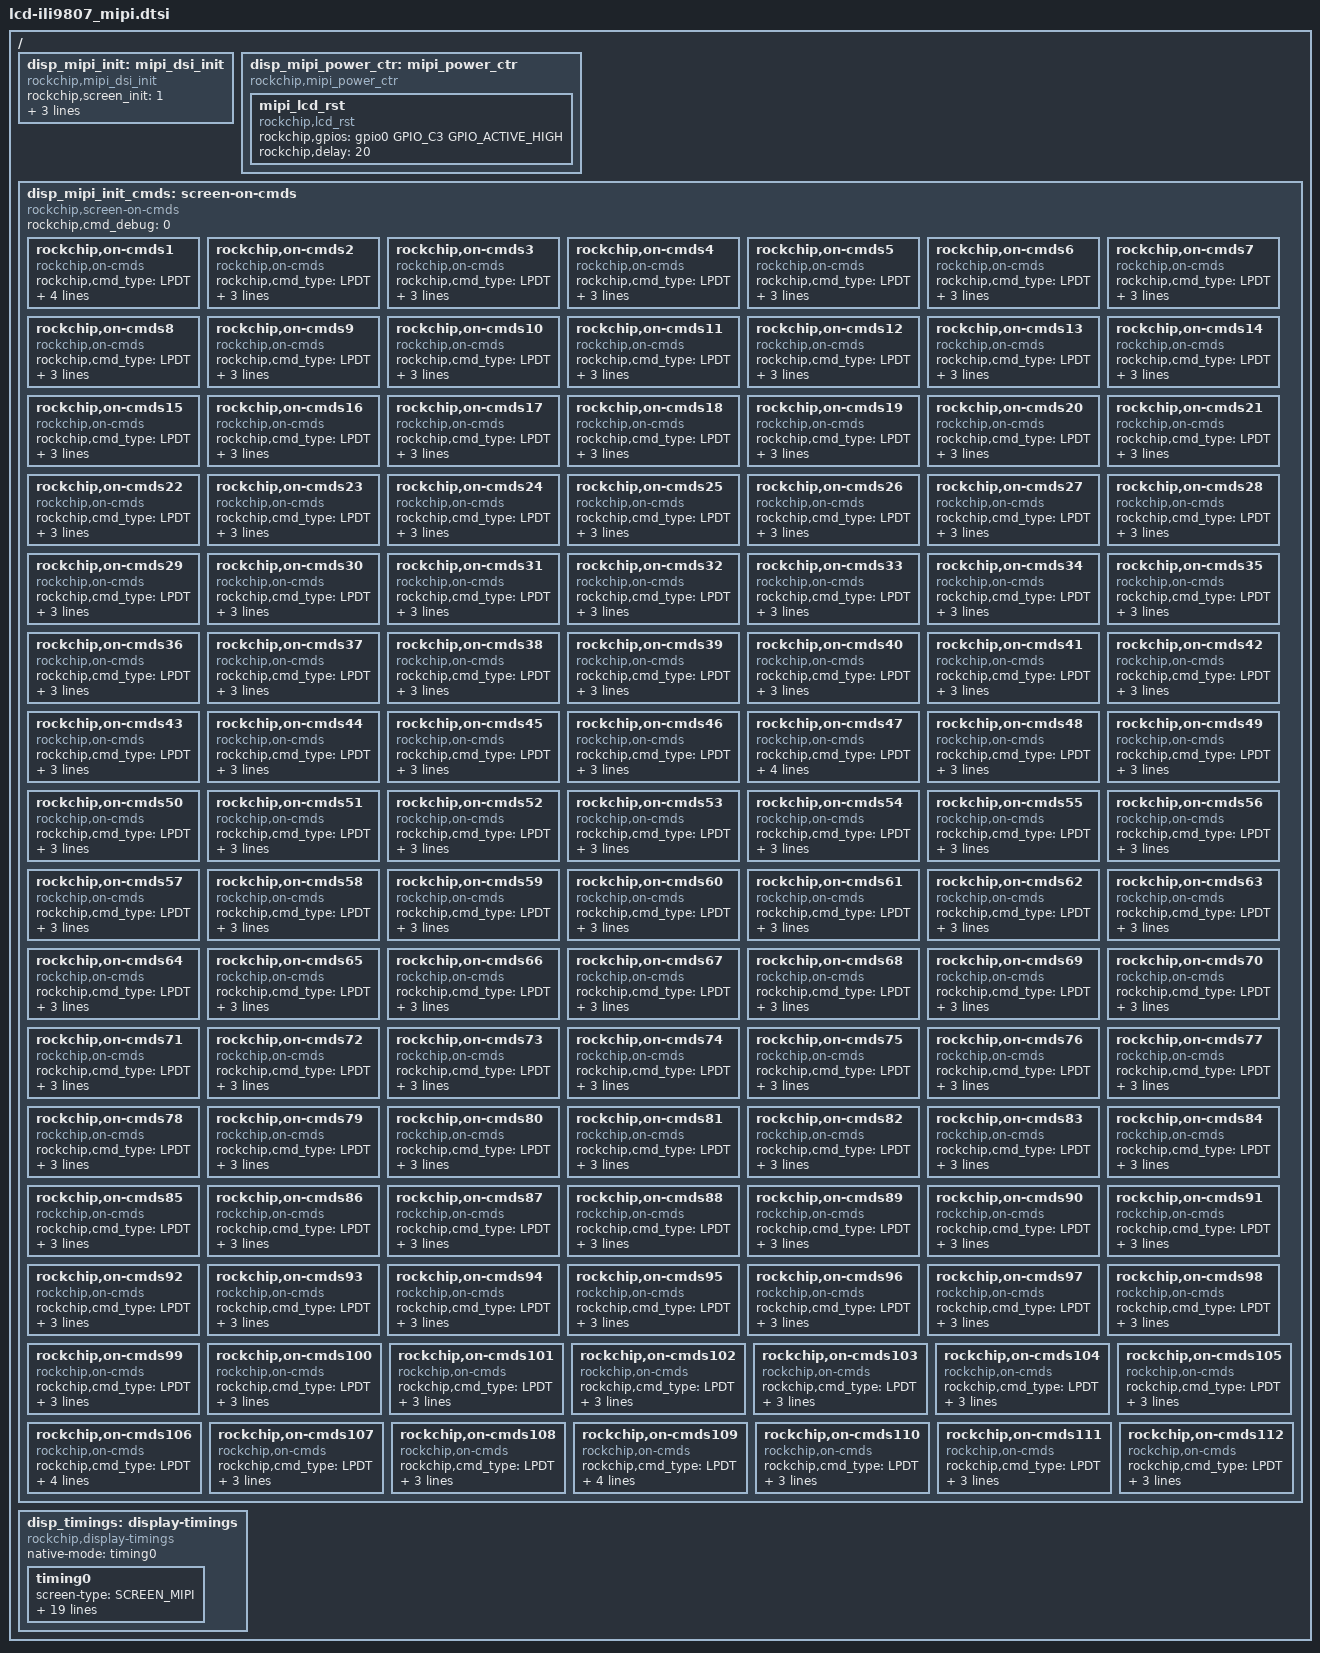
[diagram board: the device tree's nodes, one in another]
/*
 * Copyright (c) 2016 Fuzhou Rockchip Electronics Co., Ltd
 *
 * This file is dual-licensed: you can use it either under the terms
 * of the GPL or the X11 license, at your option. Note that this dual
 * licensing only applies to this file, and not this project as a
 * whole.
 *
 *  a) This file is free software; you can redistribute it and/or
 *     modify it under the terms of the GNU General Public License as
 *     published by the Free Software Foundation; either version 2 of the
 *     License, or (at your option) any later version.
 *
 *     This file is distributed in the hope that it will be useful,
 *     but WITHOUT ANY WARRANTY; without even the implied warranty of
 *     MERCHANTABILITY or FITNESS FOR A PARTICULAR PURPOSE.  See the
 *     GNU General Public License for more details.
 *
 * Or, alternatively,
 *
 *  b) Permission is hereby granted, free of charge, to any person
 *     obtaining a copy of this software and associated documentation
 *     files (the "Software"), to deal in the Software without
 *     restriction, including without limitation the rights to use,
 *     copy, modify, merge, publish, distribute, sublicense, and/or
 *     sell copies of the Software, and to permit persons to whom the
 *     Software is furnished to do so, subject to the following
 *     conditions:
 *
 *     The above copyright notice and this permission notice shall be
 *     included in all copies or substantial portions of the Software.
 *
 *     THE SOFTWARE IS PROVIDED "AS IS", WITHOUT WARRANTY OF ANY KIND,
 *     EXPRESS OR IMPLIED, INCLUDING BUT NOT LIMITED TO THE WARRANTIES
 *     OF MERCHANTABILITY, FITNESS FOR A PARTICULAR PURPOSE AND
 *     NONINFRINGEMENT. IN NO EVENT SHALL THE AUTHORS OR COPYRIGHT
 *     HOLDERS BE LIABLE FOR ANY CLAIM, DAMAGES OR OTHER LIABILITY,
 *     WHETHER IN AN ACTION OF CONTRACT, TORT OR OTHERWISE, ARISING
 *     FROM, OUT OF OR IN CONNECTION WITH THE SOFTWARE OR THE USE OR
 *     OTHER DEALINGS IN THE SOFTWARE.
 *
 * arch/arm/boot/dts/lcd_ili9807_mipi.dtsi
 * author: koben Fang
 * create date: 2016-10-18
 * lcd model: ili9807
 * resolution: 960 * 540
 * mipi channel: single
 */

/ {
	/* about mipi */
	disp_mipi_init: mipi_dsi_init{
		compatible = "rockchip,mipi_dsi_init";
		rockchip,screen_init	= <1>;
		rockchip,dsi_lane		= <2>;
		rockchip,dsi_hs_clk		= <500>;
		rockchip,mipi_dsi_num	= <1>;
	};

	disp_mipi_power_ctr: mipi_power_ctr {
		compatible = "rockchip,mipi_power_ctr";
		mipi_lcd_rst:mipi_lcd_rst{
			compatible = "rockchip,lcd_rst";
			rockchip,gpios = <&gpio0 GPIO_C3 GPIO_ACTIVE_HIGH>;
			rockchip,delay = <20>;
		};
	};

	disp_mipi_init_cmds: screen-on-cmds {
		rockchip,cmd_debug = <0>;
		compatible = "rockchip,screen-on-cmds";
		rockchip,on-cmds1 {
			compatible = "rockchip,on-cmds";
			rockchip,cmd_type = <LPDT>;
			rockchip,dsi_id = <0>;
			rockchip,cmd = <0x39 0xFF 0xFF 0x98 0x07 0x00 0x01>;
			rockchip,cmd_delay = <0>;
		};
		rockchip,on-cmds2 {
			compatible = "rockchip,on-cmds";
			rockchip,cmd_type = <LPDT>;
			rockchip,dsi_id = <0>;
			rockchip,cmd = <0x15 0x31 0x00>;
			rockchip,cmd_delay = <0>;
		};
		rockchip,on-cmds3 {
			compatible = "rockchip,on-cmds";
			rockchip,cmd_type = <LPDT>;
			rockchip,dsi_id = <0>;
			rockchip,cmd = <0x15 0x40 0x50>;
			rockchip,cmd_delay = <0>;
		};
		rockchip,on-cmds4 {
			compatible = "rockchip,on-cmds";
			rockchip,cmd_type = <LPDT>;
			rockchip,dsi_id = <0>;
			rockchip,cmd = <0x15 0x41 0x77>;
			rockchip,cmd_delay = <0>;
		};
		rockchip,on-cmds5 {
			compatible = "rockchip,on-cmds";
			rockchip,cmd_type = <LPDT>;
			rockchip,dsi_id = <0>;
			rockchip,cmd = <0x15 0x46 0xac>;
			rockchip,cmd_delay = <0>;
		};
		rockchip,on-cmds6 {
			compatible = "rockchip,on-cmds";
			rockchip,cmd_type = <LPDT>;
			rockchip,dsi_id = <0>;
			rockchip,cmd = <0x15 0x50 0x78>;
			rockchip,cmd_delay = <0>;
		};
		rockchip,on-cmds7 {
			compatible = "rockchip,on-cmds";
			rockchip,cmd_type = <LPDT>;
			rockchip,dsi_id = <0>;
			rockchip,cmd = <0x15 0x51 0x78>;
			rockchip,cmd_delay = <0>;
		};
		rockchip,on-cmds8 {
			compatible = "rockchip,on-cmds";
			rockchip,cmd_type = <LPDT>;
			rockchip,dsi_id = <0>;
			rockchip,cmd = <0x15 0x52 0x00>;
			rockchip,cmd_delay = <0>;
		};
		rockchip,on-cmds9 {
			compatible = "rockchip,on-cmds";
			rockchip,cmd_type = <LPDT>;
			rockchip,dsi_id = <0>;
			rockchip,cmd = <0x15 0x53 0x59>;
			rockchip,cmd_delay = <0>;
		};
		rockchip,on-cmds10 {
			compatible = "rockchip,on-cmds";
			rockchip,cmd_type = <LPDT>;
			rockchip,dsi_id = <0>;
			rockchip,cmd = <0x15 0x60 0x03>;
			rockchip,cmd_delay = <0>;
		};
		rockchip,on-cmds11 {
			compatible = "rockchip,on-cmds";
			rockchip,cmd_type = <LPDT>;
			rockchip,dsi_id = <0>;
			rockchip,cmd = <0x15 0x61 0x08>;
			rockchip,cmd_delay = <0>;
		};
		rockchip,on-cmds12 {
			compatible = "rockchip,on-cmds";
			rockchip,cmd_type = <LPDT>;
			rockchip,dsi_id = <0>;
			rockchip,cmd = <0x15 0x62 0x08>;
			rockchip,cmd_delay = <0>;
		};
		rockchip,on-cmds13 {
			compatible = "rockchip,on-cmds";
			rockchip,cmd_type = <LPDT>;
			rockchip,dsi_id = <0>;
			rockchip,cmd = <0x15 0x63 0x08>;
			rockchip,cmd_delay = <0>;
		};
		rockchip,on-cmds14 {
			compatible = "rockchip,on-cmds";
			rockchip,cmd_type = <LPDT>;
			rockchip,dsi_id = <0>;
			rockchip,cmd = <0x15 0x64 0x88>;
			rockchip,cmd_delay = <0>;
		};
		rockchip,on-cmds15 {
			compatible = "rockchip,on-cmds";
			rockchip,cmd_type = <LPDT>;
			rockchip,dsi_id = <0>;
			rockchip,cmd = <0x15 0xa0 0x00>;
			rockchip,cmd_delay = <0>;
		};
		rockchip,on-cmds16 {
			compatible = "rockchip,on-cmds";
			rockchip,cmd_type = <LPDT>;
			rockchip,dsi_id = <0>;
			rockchip,cmd = <0x15 0xa1 0x13>;
			rockchip,cmd_delay = <0>;
		};
		rockchip,on-cmds17 {
			compatible = "rockchip,on-cmds";
			rockchip,cmd_type = <LPDT>;
			rockchip,dsi_id = <0>;
			rockchip,cmd = <0x15 0xa2 0x1c>;
			rockchip,cmd_delay = <0>;
		};
		rockchip,on-cmds18 {
			compatible = "rockchip,on-cmds";
			rockchip,cmd_type = <LPDT>;
			rockchip,dsi_id = <0>;
			rockchip,cmd = <0x15 0xa3 0x0e>;
			rockchip,cmd_delay = <0>;
		};
		rockchip,on-cmds19 {
			compatible = "rockchip,on-cmds";
			rockchip,cmd_type = <LPDT>;
			rockchip,dsi_id = <0>;
			rockchip,cmd = <0x15 0xa4 0x07>;
			rockchip,cmd_delay = <0>;
		};
		rockchip,on-cmds20 {
			compatible = "rockchip,on-cmds";
			rockchip,cmd_type = <LPDT>;
			rockchip,dsi_id = <0>;
			rockchip,cmd = <0x15 0xa5 0x0d>;
			rockchip,cmd_delay = <0>;
		};
		rockchip,on-cmds21 {
			compatible = "rockchip,on-cmds";
			rockchip,cmd_type = <LPDT>;
			rockchip,dsi_id = <0>;
			rockchip,cmd = <0x15 0xA6 0x08>;
			rockchip,cmd_delay = <0>;
		};
		rockchip,on-cmds22 {
			compatible = "rockchip,on-cmds";
			rockchip,cmd_type = <LPDT>;
			rockchip,dsi_id = <0>;
			rockchip,cmd = <0x15 0xA7 0x06>;
			rockchip,cmd_delay = <0>;
		};
		rockchip,on-cmds23 {
			compatible = "rockchip,on-cmds";
			rockchip,cmd_type = <LPDT>;
			rockchip,dsi_id = <0>;
			rockchip,cmd = <0x15 0xA8 0x05>;
			rockchip,cmd_delay = <0>;
		};
		rockchip,on-cmds24 {
			compatible = "rockchip,on-cmds";
			rockchip,cmd_type = <LPDT>;
			rockchip,dsi_id = <0>;
			rockchip,cmd = <0x15 0xA9 0x0a>;
			rockchip,cmd_delay = <0>;
		};
		rockchip,on-cmds25 {
			compatible = "rockchip,on-cmds";
			rockchip,cmd_type = <LPDT>;
			rockchip,dsi_id = <0>;
			rockchip,cmd = <0x15 0xAA 0x0e>;
			rockchip,cmd_delay = <0>;
		};
		rockchip,on-cmds26 {
			compatible = "rockchip,on-cmds";
			rockchip,cmd_type = <LPDT>;
			rockchip,dsi_id = <0>;
			rockchip,cmd = <0x15 0xAB 0x06>;
			rockchip,cmd_delay = <0>;
		};
		rockchip,on-cmds27 {
			compatible = "rockchip,on-cmds";
			rockchip,cmd_type = <LPDT>;
			rockchip,dsi_id = <0>;
			rockchip,cmd = <0x15 0xAC 0x0C>;
			rockchip,cmd_delay = <0>;
		};
		rockchip,on-cmds28 {
			compatible = "rockchip,on-cmds";
			rockchip,cmd_type = <LPDT>;
			rockchip,dsi_id = <0>;
			rockchip,cmd = <0x15 0xAD 0x11>;
			rockchip,cmd_delay = <0>;
		};
		rockchip,on-cmds29 {
			compatible = "rockchip,on-cmds";
			rockchip,cmd_type = <LPDT>;
			rockchip,dsi_id = <0>;
			rockchip,cmd = <0x15 0xAE 0x0A>;
			rockchip,cmd_delay = <0>;
		};
		rockchip,on-cmds30 {
			compatible = "rockchip,on-cmds";
			rockchip,cmd_type = <LPDT>;
			rockchip,dsi_id = <0>;
			rockchip,cmd = <0x15 0xAF 0x00>;
			rockchip,cmd_delay = <0>;
		};
		rockchip,on-cmds31 {
		compatible = "rockchip,on-cmds";
			rockchip,cmd_type = <LPDT>;
			rockchip,dsi_id = <0>;
			rockchip,cmd = <0x15 0xC0 0x00>;
			rockchip,cmd_delay = <0>;
		};
		rockchip,on-cmds32 {
			compatible = "rockchip,on-cmds";
			rockchip,cmd_type = <LPDT>;
			rockchip,dsi_id = <0>;
			rockchip,cmd = <0x15 0xC1 0x13>;
			rockchip,cmd_delay = <0>;
		};
		rockchip,on-cmds33 {
			compatible = "rockchip,on-cmds";
			rockchip,cmd_type = <LPDT>;
			rockchip,dsi_id = <0>;
			rockchip,cmd = <0x15 0xC2 0x1C>;
			rockchip,cmd_delay = <0>;
		};
		rockchip,on-cmds34 {
			compatible = "rockchip,on-cmds";
			rockchip,cmd_type = <LPDT>;
			rockchip,dsi_id = <0>;
			rockchip,cmd = <0x15 0xC3 0x04>;
			rockchip,cmd_delay = <0>;
		};
		rockchip,on-cmds35 {
			compatible = "rockchip,on-cmds";
			rockchip,cmd_type = <LPDT>;
			rockchip,dsi_id = <0>;
			rockchip,cmd = <0x15 0xC4 0x06>;
			rockchip,cmd_delay = <0>;
		};
		rockchip,on-cmds36 {
			compatible = "rockchip,on-cmds";
			rockchip,cmd_type = <LPDT>;
			rockchip,dsi_id = <0>;
			rockchip,cmd = <0x15 0xC5 0x0D>;
			rockchip,cmd_delay = <0>;
		};
		rockchip,on-cmds37 {
			compatible = "rockchip,on-cmds";
			rockchip,cmd_type = <LPDT>;
			rockchip,dsi_id = <0>;
			rockchip,cmd = <0x15 0xC6 0x08>;
			rockchip,cmd_delay = <0>;
		};
		rockchip,on-cmds38 {
			compatible = "rockchip,on-cmds";
			rockchip,cmd_type = <LPDT>;
			rockchip,dsi_id = <0>;
			rockchip,cmd = <0x15 0xC7 0x07>;
			rockchip,cmd_delay = <0>;
		};
		rockchip,on-cmds39 {
			compatible = "rockchip,on-cmds";
			rockchip,cmd_type = <LPDT>;
			rockchip,dsi_id = <0>;
			rockchip,cmd = <0x15 0xC8 0x05>;
			rockchip,cmd_delay = <0>;
		};
		rockchip,on-cmds40 {
			compatible = "rockchip,on-cmds";
			rockchip,cmd_type = <LPDT>;
			rockchip,dsi_id = <0>;
			rockchip,cmd = <0x15 0xC9 0x0A>;
			rockchip,cmd_delay = <0>;
		};
		rockchip,on-cmds41 {
			compatible = "rockchip,on-cmds";
			rockchip,cmd_type = <LPDT>;
			rockchip,dsi_id = <0>;
			rockchip,cmd = <0x15 0xCA 0x0E>;
			rockchip,cmd_delay = <0>;
		};
		rockchip,on-cmds42 {
			compatible = "rockchip,on-cmds";
			rockchip,cmd_type = <LPDT>;
			rockchip,dsi_id = <0>;
			rockchip,cmd = <0x15 0xCB 0x07>;
			rockchip,cmd_delay = <0>;
		};
		rockchip,on-cmds43 {
			compatible = "rockchip,on-cmds";
			rockchip,cmd_type = <LPDT>;
			rockchip,dsi_id = <0>;
			rockchip,cmd = <0x15 0xCC 0x0D>;
			rockchip,cmd_delay = <0>;
		};
		rockchip,on-cmds44 {
			compatible = "rockchip,on-cmds";
			rockchip,cmd_type = <LPDT>;
			rockchip,dsi_id = <0>;
			rockchip,cmd = <0x15 0xCD 0x11>;
			rockchip,cmd_delay = <0>;
		};
		rockchip,on-cmds45 {
			compatible = "rockchip,on-cmds";
			rockchip,cmd_type = <LPDT>;
			rockchip,dsi_id = <0>;
			rockchip,cmd = <0x15 0xCE 0x0A>;
			rockchip,cmd_delay = <0>;
		};
		rockchip,on-cmds46 {
			compatible = "rockchip,on-cmds";
			rockchip,cmd_type = <LPDT>;
			rockchip,dsi_id = <0>;
			rockchip,cmd = <0x15 0xCF 0x00>;
			rockchip,cmd_delay = <0>;
		};
		rockchip,on-cmds47 {
			compatible = "rockchip,on-cmds";
			rockchip,cmd_type = <LPDT>;
			rockchip,dsi_id = <0>;
			rockchip,cmd = <0x39 0xFF 0xFF 0x98 0x07 0x00 0x06>;
			rockchip,cmd_delay = <0>;
		};
		rockchip,on-cmds48 {
			compatible = "rockchip,on-cmds";
			rockchip,cmd_type = <LPDT>;
			rockchip,dsi_id = <0>;
			rockchip,cmd = <0x15 0x00 0x21>;
			rockchip,cmd_delay = <0>;
		};
		rockchip,on-cmds49 {
			compatible = "rockchip,on-cmds";
			rockchip,cmd_type = <LPDT>;
			rockchip,dsi_id = <0>;
			rockchip,cmd = <0x15 0x01 0x0A>;
			rockchip,cmd_delay = <0>;
		};
		rockchip,on-cmds50 {
			compatible = "rockchip,on-cmds";
			rockchip,cmd_type = <LPDT>;
			rockchip,dsi_id = <0>;
			rockchip,cmd = <0x15 0x02 0x00>;
			rockchip,cmd_delay = <0>;
		};
		rockchip,on-cmds51 {
			compatible = "rockchip,on-cmds";
			rockchip,cmd_type = <LPDT>;
			rockchip,dsi_id = <0>;
			rockchip,cmd = <0x15 0x03 0x00>;
			rockchip,cmd_delay = <0>;
		};
		rockchip,on-cmds52 {
			compatible = "rockchip,on-cmds";
			rockchip,cmd_type = <LPDT>;
			rockchip,dsi_id = <0>;
			rockchip,cmd = <0x15 0x04 0x0A>;
			rockchip,cmd_delay = <0>;
		};
		rockchip,on-cmds53 {
			compatible = "rockchip,on-cmds";
			rockchip,cmd_type = <LPDT>;
			rockchip,dsi_id = <0>;
			rockchip,cmd = <0x15 0x05 0x01>;
			rockchip,cmd_delay = <0>;
		};
		rockchip,on-cmds54 {
			compatible = "rockchip,on-cmds";
			rockchip,cmd_type = <LPDT>;
			rockchip,dsi_id = <0>;
			rockchip,cmd = <0x15 0x06 0x80>;
			rockchip,cmd_delay = <0>;
		};
		rockchip,on-cmds55 {
			compatible = "rockchip,on-cmds";
			rockchip,cmd_type = <LPDT>;
			rockchip,dsi_id = <0>;
			rockchip,cmd = <0x15 0x07 0x06>;
			rockchip,cmd_delay = <0>;
		};
		rockchip,on-cmds56 {
			compatible = "rockchip,on-cmds";
			rockchip,cmd_type = <LPDT>;
			rockchip,dsi_id = <0>;
			rockchip,cmd = <0x15 0x08 0x01>;
			rockchip,cmd_delay = <0>;
		};
		rockchip,on-cmds57 {
			compatible = "rockchip,on-cmds";
			rockchip,cmd_type = <LPDT>;
			rockchip,dsi_id = <0>;
			rockchip,cmd = <0x15 0x09 0x00>;
			rockchip,cmd_delay = <0>;
		};
		rockchip,on-cmds58 {
			compatible = "rockchip,on-cmds";
			rockchip,cmd_type = <LPDT>;
			rockchip,dsi_id = <0>;
			rockchip,cmd = <0x15 0x0A 0x00>;
			rockchip,cmd_delay = <0>;
		};
		rockchip,on-cmds59 {
			compatible = "rockchip,on-cmds";
			rockchip,cmd_type = <LPDT>;
			rockchip,dsi_id = <0>;
			rockchip,cmd = <0x15 0x0B 0x00>;
			rockchip,cmd_delay = <0>;
		};
		rockchip,on-cmds60 {
			compatible = "rockchip,on-cmds";
			rockchip,cmd_type = <LPDT>;
			rockchip,dsi_id = <0>;
			rockchip,cmd = <0x15 0x0C 0x01>;
			rockchip,cmd_delay = <0>;
		};
		rockchip,on-cmds61 {
			compatible = "rockchip,on-cmds";
			rockchip,cmd_type = <LPDT>;
			rockchip,dsi_id = <0>;
			rockchip,cmd = <0x15 0x0D 0x01>;
			rockchip,cmd_delay = <0>;
		};
		rockchip,on-cmds62 {
			compatible = "rockchip,on-cmds";
			rockchip,cmd_type = <LPDT>;
			rockchip,dsi_id = <0>;
			rockchip,cmd = <0x15 0x0E 0x08>;
			rockchip,cmd_delay = <0>;
		};
		rockchip,on-cmds63 {
			compatible = "rockchip,on-cmds";
			rockchip,cmd_type = <LPDT>;
			rockchip,dsi_id = <0>;
			rockchip,cmd = <0x15 0x0F 0x00>;
			rockchip,cmd_delay = <0>;
		};
		rockchip,on-cmds64 {
			compatible = "rockchip,on-cmds";
			rockchip,cmd_type = <LPDT>;
			rockchip,dsi_id = <0>;
			rockchip,cmd = <0x15 0x10 0xF0>;
			rockchip,cmd_delay = <0>;
		};
		rockchip,on-cmds65 {
			compatible = "rockchip,on-cmds";
			rockchip,cmd_type = <LPDT>;
			rockchip,dsi_id = <0>;
			rockchip,cmd = <0x15 0x11 0xF0>;
			rockchip,cmd_delay = <0>;
		};
		rockchip,on-cmds66 {
			compatible = "rockchip,on-cmds";
			rockchip,cmd_type = <LPDT>;
			rockchip,dsi_id = <0>;
			rockchip,cmd = <0x15 0x12 0x01>;
			rockchip,cmd_delay = <0>;
		};
		rockchip,on-cmds67 {
			compatible = "rockchip,on-cmds";
			rockchip,cmd_type = <LPDT>;
			rockchip,dsi_id = <0>;
			rockchip,cmd = <0x15 0x13 0x00>;
			rockchip,cmd_delay = <0>;
		};
		rockchip,on-cmds68 {
			compatible = "rockchip,on-cmds";
			rockchip,cmd_type = <LPDT>;
			rockchip,dsi_id = <0>;
			rockchip,cmd = <0x15 0x14 0x00>;
			rockchip,cmd_delay = <0>;
		};
		rockchip,on-cmds69 {
			compatible = "rockchip,on-cmds";
			rockchip,cmd_type = <LPDT>;
			rockchip,dsi_id = <0>;
			rockchip,cmd = <0x15 0x15 0xC0>;
			rockchip,cmd_delay = <0>;
		};
		rockchip,on-cmds70 {
			compatible = "rockchip,on-cmds";
			rockchip,cmd_type = <LPDT>;
			rockchip,dsi_id = <0>;
			rockchip,cmd = <0x15 0x16 0x08>;
			rockchip,cmd_delay = <0>;
		};
		rockchip,on-cmds71 {
			compatible = "rockchip,on-cmds";
			rockchip,cmd_type = <LPDT>;
			rockchip,dsi_id = <0>;
			rockchip,cmd = <0x15 0x17 0x00>;
			rockchip,cmd_delay = <0>;
		};
		rockchip,on-cmds72 {
			compatible = "rockchip,on-cmds";
			rockchip,cmd_type = <LPDT>;
			rockchip,dsi_id = <0>;
			rockchip,cmd = <0x15 0x18 0x00>;
			rockchip,cmd_delay = <0>;
		};
		rockchip,on-cmds73 {
			compatible = "rockchip,on-cmds";
			rockchip,cmd_type = <LPDT>;
			rockchip,dsi_id = <0>;
			rockchip,cmd = <0x15 0x19 0x00>;
			rockchip,cmd_delay = <0>;
		};
		rockchip,on-cmds74 {
			compatible = "rockchip,on-cmds";
			rockchip,cmd_type = <LPDT>;
			rockchip,dsi_id = <0>;
			rockchip,cmd = <0x15 0x1A 0x00>;
			rockchip,cmd_delay = <0>;
		};
		rockchip,on-cmds75 {
			compatible = "rockchip,on-cmds";
			rockchip,cmd_type = <LPDT>;
			rockchip,dsi_id = <0>;
			rockchip,cmd = <0x15 0x1B 0x00>;
			rockchip,cmd_delay = <0>;
		};
		rockchip,on-cmds76 {
			compatible = "rockchip,on-cmds";
			rockchip,cmd_type = <LPDT>;
			rockchip,dsi_id = <0>;
			rockchip,cmd = <0x15 0x1C 0x00>;
			rockchip,cmd_delay = <0>;
		};
		rockchip,on-cmds77 {
			compatible = "rockchip,on-cmds";
			rockchip,cmd_type = <LPDT>;
			rockchip,dsi_id = <0>;
			rockchip,cmd = <0x15 0x1D 0x00>;
			rockchip,cmd_delay = <0>;
		};
		rockchip,on-cmds78 {
			compatible = "rockchip,on-cmds";
			rockchip,cmd_type = <LPDT>;
			rockchip,dsi_id = <0>;
			rockchip,cmd = <0x15 0x20 0x01>;
			rockchip,cmd_delay = <0>;
		};
		rockchip,on-cmds79 {
			compatible = "rockchip,on-cmds";
			rockchip,cmd_type = <LPDT>;
			rockchip,dsi_id = <0>;
			rockchip,cmd = <0x15 0x21 0x023>;
			rockchip,cmd_delay = <0>;
		};
		rockchip,on-cmds80 {
			compatible = "rockchip,on-cmds";
			rockchip,cmd_type = <LPDT>;
			rockchip,dsi_id = <0>;
			rockchip,cmd = <0x15 0x22 0x45>;
			rockchip,cmd_delay = <0>;
		};
		rockchip,on-cmds81 {
			compatible = "rockchip,on-cmds";
			rockchip,cmd_type = <LPDT>;
			rockchip,dsi_id = <0>;
			rockchip,cmd = <0x15 0x23 0x67>;
			rockchip,cmd_delay = <0>;
		};
		rockchip,on-cmds82 {
			compatible = "rockchip,on-cmds";
			rockchip,cmd_type = <LPDT>;
			rockchip,dsi_id = <0>;
			rockchip,cmd = <0x15 0x24 0x01>;
			rockchip,cmd_delay = <0>;
		};
		rockchip,on-cmds83 {
			compatible = "rockchip,on-cmds";
			rockchip,cmd_type = <LPDT>;
			rockchip,dsi_id = <0>;
			rockchip,cmd = <0x15 0x25 0x23>;
			rockchip,cmd_delay = <0>;
		};
		rockchip,on-cmds84 {
			compatible = "rockchip,on-cmds";
			rockchip,cmd_type = <LPDT>;
			rockchip,dsi_id = <0>;
			rockchip,cmd = <0x15 0x26 0x45>;
			rockchip,cmd_delay = <0>;
		};
		rockchip,on-cmds85 {
			compatible = "rockchip,on-cmds";
			rockchip,cmd_type = <LPDT>;
			rockchip,dsi_id = <0>;
			rockchip,cmd = <0x15 0x27 0x67>;
			rockchip,cmd_delay = <0>;
		};
		rockchip,on-cmds86 {
			compatible = "rockchip,on-cmds";
			rockchip,cmd_type = <LPDT>;
			rockchip,dsi_id = <0>;
			rockchip,cmd = <0x15 0x30 0x01>;
			rockchip,cmd_delay = <0>;
		};
		rockchip,on-cmds87 {
			compatible = "rockchip,on-cmds";
			rockchip,cmd_type = <LPDT>;
			rockchip,dsi_id = <0>;
			rockchip,cmd = <0x15 0x31 0x11>;
			rockchip,cmd_delay = <0>;
		};
		rockchip,on-cmds88 {
			compatible = "rockchip,on-cmds";
			rockchip,cmd_type = <LPDT>;
			rockchip,dsi_id = <0>;
			rockchip,cmd = <0x15 0x32 0x00>;
			rockchip,cmd_delay = <0>;
		};
		rockchip,on-cmds89 {
			compatible = "rockchip,on-cmds";
			rockchip,cmd_type = <LPDT>;
			rockchip,dsi_id = <0>;
			rockchip,cmd = <0x15 0x33 0xEE>;
			rockchip,cmd_delay = <0>;
		};
		rockchip,on-cmds90 {
			compatible = "rockchip,on-cmds";
			rockchip,cmd_type = <LPDT>;
			rockchip,dsi_id = <0>;
			rockchip,cmd = <0x15 0x34 0xFF>;
			rockchip,cmd_delay = <0>;
		};
		rockchip,on-cmds91 {
			compatible = "rockchip,on-cmds";
			rockchip,cmd_type = <LPDT>;
			rockchip,dsi_id = <0>;
			rockchip,cmd = <0x15 0x35 0x22>;
			rockchip,cmd_delay = <0>;
		};
		rockchip,on-cmds92 {
			compatible = "rockchip,on-cmds";
			rockchip,cmd_type = <LPDT>;
			rockchip,dsi_id = <0>;
			rockchip,cmd = <0x15 0x36 0xCB>;
			rockchip,cmd_delay = <0>;
		};
		rockchip,on-cmds93 {
			compatible = "rockchip,on-cmds";
			rockchip,cmd_type = <LPDT>;
			rockchip,dsi_id = <0>;
			rockchip,cmd = <0x15 0x37 0x22>;
			rockchip,cmd_delay = <0>;
		};
		rockchip,on-cmds94 {
			compatible = "rockchip,on-cmds";
			rockchip,cmd_type = <LPDT>;
			rockchip,dsi_id = <0>;
			rockchip,cmd = <0x15 0x38 0xDA>;
			rockchip,cmd_delay = <0>;
		};
		rockchip,on-cmds95 {
			compatible = "rockchip,on-cmds";
			rockchip,cmd_type = <LPDT>;
			rockchip,dsi_id = <0>;
			rockchip,cmd = <0x15 0x39 0x22>;
			rockchip,cmd_delay = <0>;
		};
		rockchip,on-cmds96 {
			compatible = "rockchip,on-cmds";
			rockchip,cmd_type = <LPDT>;
			rockchip,dsi_id = <0>;
			rockchip,cmd = <0x15 0x3A 0xAD>;
			rockchip,cmd_delay = <0>;
		};
		rockchip,on-cmds97 {
			compatible = "rockchip,on-cmds";
			rockchip,cmd_type = <LPDT>;
			rockchip,dsi_id = <0>;
			rockchip,cmd = <0x15 0x3B 0x22>;
			rockchip,cmd_delay = <0>;
		};
		rockchip,on-cmds98 {
			compatible = "rockchip,on-cmds";
			rockchip,cmd_type = <LPDT>;
			rockchip,dsi_id = <0>;
			rockchip,cmd = <0x15 0x3C 0xBC>;
			rockchip,cmd_delay = <0>;
		};
		rockchip,on-cmds99 {
			compatible = "rockchip,on-cmds";
			rockchip,cmd_type = <LPDT>;
			rockchip,dsi_id = <0>;
			rockchip,cmd = <0x15 0x3D 0x76>;
			rockchip,cmd_delay = <0>;
		};
		rockchip,on-cmds100 {
			compatible = "rockchip,on-cmds";
			rockchip,cmd_type = <LPDT>;
			rockchip,dsi_id = <0>;
			rockchip,cmd = <0x15 0x3E 0x67>;
			rockchip,cmd_delay = <0>;
		};
		rockchip,on-cmds101 {
			compatible = "rockchip,on-cmds";
			rockchip,cmd_type = <LPDT>;
			rockchip,dsi_id = <0>;
			rockchip,cmd = <0x15 0x3F 0x22>;
			rockchip,cmd_delay = <0>;
		};
		rockchip,on-cmds102 {
			compatible = "rockchip,on-cmds";
			rockchip,cmd_type = <LPDT>;
			rockchip,dsi_id = <0>;
			rockchip,cmd = <0x15 0x40 0x22>;
			rockchip,cmd_delay = <0>;
		};
		rockchip,on-cmds103 {
			compatible = "rockchip,on-cmds";
			rockchip,cmd_type = <LPDT>;
			rockchip,dsi_id = <0>;
			rockchip,cmd = <0x15 0x41 0x22>;
			rockchip,cmd_delay = <0>;
		};
		rockchip,on-cmds104 {
			compatible = "rockchip,on-cmds";
			rockchip,cmd_type = <LPDT>;
			rockchip,dsi_id = <0>;
			rockchip,cmd = <0x15 0x42 0x22>;
			rockchip,cmd_delay = <0>;
		};
		rockchip,on-cmds105 {
			compatible = "rockchip,on-cmds";
			rockchip,cmd_type = <LPDT>;
			rockchip,dsi_id = <0>;
			rockchip,cmd = <0x15 0x43 0x22>;
			rockchip,cmd_delay = <0>;
		};
		rockchip,on-cmds106 {
			compatible = "rockchip,on-cmds";
			rockchip,cmd_type = <LPDT>;
			rockchip,dsi_id = <0>;
			rockchip,cmd = <0x39 0xFF 0xFF 0x98 0x07 0x00 0x07>;
			rockchip,cmd_delay = <0>;
		};
		rockchip,on-cmds107 {
			compatible = "rockchip,on-cmds";
			rockchip,cmd_type = <LPDT>;
			rockchip,dsi_id = <0>;
			rockchip,cmd = <0x15 0x02 0x77>;
			rockchip,cmd_delay = <0>;
		};
		rockchip,on-cmds108 {
			compatible = "rockchip,on-cmds";
			rockchip,cmd_type = <LPDT>;
			rockchip,dsi_id = <0>;
			rockchip,cmd = <0x15 0x18 0x1D>;
			rockchip,cmd_delay = <0>;
		};
		rockchip,on-cmds109 {
			compatible = "rockchip,on-cmds";
			rockchip,cmd_type = <LPDT>;
			rockchip,dsi_id = <0>;
			rockchip,cmd = <0x39 0xFF 0xFF 0x98 0x07 0x00 0x00>;
			rockchip,cmd_delay = <0>;
		};
		rockchip,on-cmds110 {
			compatible = "rockchip,on-cmds";
			rockchip,cmd_type = <LPDT>;
			rockchip,dsi_id = <0>;
			rockchip,cmd = <0x15 0x35 0x00>;
			rockchip,cmd_delay = <0>;
		};
		rockchip,on-cmds111 {
			compatible = "rockchip,on-cmds";
			rockchip,cmd_type = <LPDT>;
			rockchip,dsi_id = <0>;
			rockchip,cmd = <0x15 0x11 0x00>;
			rockchip,cmd_delay = <120>;
		};
		rockchip,on-cmds112 {
			compatible = "rockchip,on-cmds";
			rockchip,cmd_type = <LPDT>;
			rockchip,dsi_id = <0>;
			rockchip,cmd = <0x15 0x29 0x00>;
			rockchip,cmd_delay = <200>;
		};
	};

	disp_timings: display-timings {
		native-mode = <&timing0>;
		compatible = "rockchip,display-timings";
		timing0: timing0 {
			screen-type = <SCREEN_MIPI>;
			/*lvds-format = <LVDS_8BIT_2>;*/
			out-face    = <OUT_P888>;
			clock-frequency = <35390050>;
			screen-width = <62>;
			screen-hight = <110>;
			hactive = <540>;
			vactive = <960>;
			hsync-len = <8>;
			hback-porch = <85>;
			hfront-porch = <85>;
			vsync-len = <1>;
			vback-porch = <20>;
			vfront-porch = <20>;
			hsync-active = <0>;
			vsync-active = <0>;
			de-active = <0>;
			pixelclk-active = <0>;
			swap-rb = <0>;
			swap-rg = <0>;
			swap-gb = <0>;
		};
	};
};
